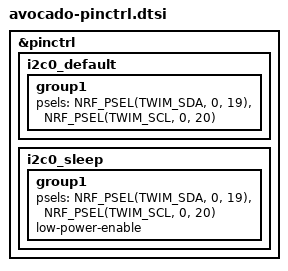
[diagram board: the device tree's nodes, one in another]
&pinctrl {
    /* configuration for i2c0 device, default state */
    i2c0_default: i2c0_default {
        group1 {
            psels = <NRF_PSEL(TWIM_SDA, 0, 19)>,
                <NRF_PSEL(TWIM_SCL, 0, 20)>;
        };
    };

    i2c0_sleep: i2c0_sleep {
        group1 {
            psels = <NRF_PSEL(TWIM_SDA, 0, 19)>,
                <NRF_PSEL(TWIM_SCL, 0, 20)>;
            low-power-enable;
        };
    };
};
